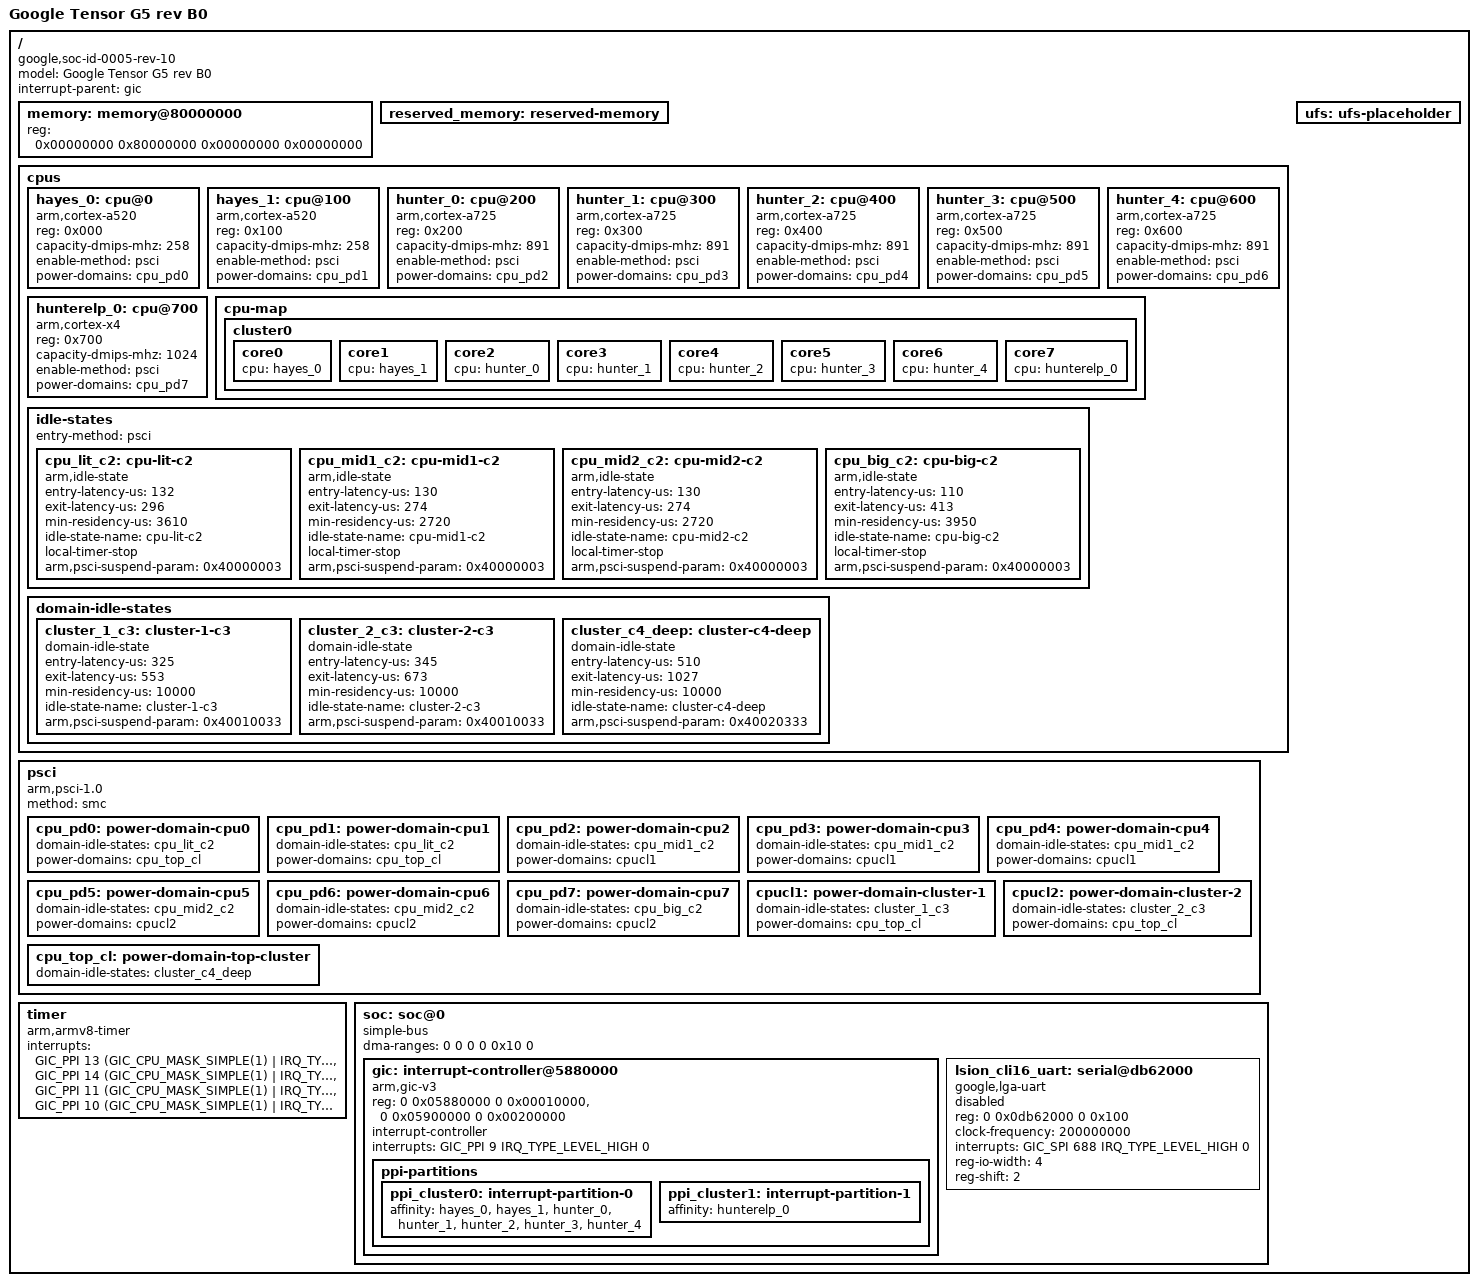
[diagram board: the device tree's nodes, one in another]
// SPDX-License-Identifier: GPL-2.0 OR BSD-3-Clause
/*
 * Google Tensor G5 (laguna) SoC rev B0
 *
 * Copyright 2024-2025 Google LLC.
 */

/dts-v1/;

#include <dt-bindings/interrupt-controller/arm-gic.h>
#include <dt-bindings/interrupt-controller/irq.h>

/ {
	model = "Google Tensor G5 rev B0";
	compatible = "google,soc-id-0005-rev-10", "google,lga";
	#address-cells = <2>;
	#size-cells = <2>;
	interrupt-parent = <&gic>;

	memory: memory@80000000 {
		device_type = "memory";
		/* We expect the bootloader to fill in the size */
		reg = <0x00000000 0x80000000 0x00000000 0x00000000>;
	};

	reserved_memory: reserved-memory {
		#address-cells = <2>;
		#size-cells = <2>;
		ranges;
	};

	cpus: cpus {
		#address-cells = <1>;
		#size-cells = <0>;

		hayes_0: cpu@0 {
			compatible = "arm,cortex-a520";
			reg = <0x000>;

			#cooling-cells = <2>;
			capacity-dmips-mhz = <258>;
			device_type = "cpu";
			enable-method = "psci";
			power-domain-names = "psci";
			power-domains = <&cpu_pd0>;
		};

		hayes_1: cpu@100 {
			compatible = "arm,cortex-a520";
			reg = <0x100>;

			#cooling-cells = <2>;
			capacity-dmips-mhz = <258>;
			device_type = "cpu";
			enable-method = "psci";
			power-domain-names = "psci";
			power-domains = <&cpu_pd1>;
		};

		hunter_0: cpu@200 {
			compatible = "arm,cortex-a725";
			reg = <0x200>;

			#cooling-cells = <2>;
			capacity-dmips-mhz = <891>;
			device_type = "cpu";
			enable-method = "psci";
			power-domain-names = "psci";
			power-domains = <&cpu_pd2>;
		};

		hunter_1: cpu@300 {
			compatible = "arm,cortex-a725";
			reg = <0x300>;

			#cooling-cells = <2>;
			capacity-dmips-mhz = <891>;
			device_type = "cpu";
			enable-method = "psci";
			power-domain-names = "psci";
			power-domains = <&cpu_pd3>;
		};

		hunter_2: cpu@400 {
			compatible = "arm,cortex-a725";
			reg = <0x400>;

			#cooling-cells = <2>;
			capacity-dmips-mhz = <891>;
			device_type = "cpu";
			enable-method = "psci";
			power-domain-names = "psci";
			power-domains = <&cpu_pd4>;
		};

		hunter_3: cpu@500 {
			compatible = "arm,cortex-a725";
			reg = <0x500>;

			#cooling-cells = <2>;
			capacity-dmips-mhz = <891>;
			device_type = "cpu";
			enable-method = "psci";
			power-domain-names = "psci";
			power-domains = <&cpu_pd5>;
		};

		hunter_4: cpu@600 {
			compatible = "arm,cortex-a725";
			reg = <0x600>;

			#cooling-cells = <2>;
			capacity-dmips-mhz = <891>;
			device_type = "cpu";
			enable-method = "psci";
			power-domain-names = "psci";
			power-domains = <&cpu_pd6>;
		};

		hunterelp_0: cpu@700 {
			compatible = "arm,cortex-x4";
			reg = <0x700>;

			#cooling-cells = <2>;
			capacity-dmips-mhz = <1024>;
			device_type = "cpu";
			enable-method = "psci";
			power-domain-names = "psci";
			power-domains = <&cpu_pd7>;
		};

		cpu-map {
			cluster0 {
				core0 {
					cpu = <&hayes_0>;
				};
				core1 {
					cpu = <&hayes_1>;
				};
				core2 {
					cpu = <&hunter_0>;
				};
				core3 {
					cpu = <&hunter_1>;
				};
				core4 {
					cpu = <&hunter_2>;
				};
				core5 {
					cpu = <&hunter_3>;
				};
				core6 {
					cpu = <&hunter_4>;
				};
				core7 {
					cpu = <&hunterelp_0>;
				};
			};
		};

		idle-states {
			entry-method = "psci";

			cpu_lit_c2: cpu-lit-c2 {
				compatible = "arm,idle-state";

				entry-latency-us = <132>;
				exit-latency-us = <296>;
				min-residency-us = <3610>;

				idle-state-name = "cpu-lit-c2";
				local-timer-stop;

				arm,psci-suspend-param = <0x40000003>;
			};

			cpu_mid1_c2: cpu-mid1-c2 {
				compatible = "arm,idle-state";

				entry-latency-us = <130>;
				exit-latency-us = <274>;
				min-residency-us = <2720>;

				idle-state-name = "cpu-mid1-c2";
				local-timer-stop;

				arm,psci-suspend-param = <0x40000003>;
			};

			cpu_mid2_c2: cpu-mid2-c2 {
				compatible = "arm,idle-state";

				entry-latency-us = <130>;
				exit-latency-us = <274>;
				min-residency-us = <2720>;

				idle-state-name = "cpu-mid2-c2";
				local-timer-stop;

				arm,psci-suspend-param = <0x40000003>;
			};

			cpu_big_c2: cpu-big-c2 {
				compatible = "arm,idle-state";

				entry-latency-us = <110>;
				exit-latency-us = <413>;
				min-residency-us = <3950>;

				idle-state-name = "cpu-big-c2";
				local-timer-stop;

				arm,psci-suspend-param = <0x40000003>;
			};
		};

		domain-idle-states {
			cluster_1_c3: cluster-1-c3 {
				compatible = "domain-idle-state";

				entry-latency-us = <325>;
				exit-latency-us = <553>;
				min-residency-us = <10000>;

				idle-state-name = "cluster-1-c3";

				arm,psci-suspend-param = <0x40010033>;
			};

			cluster_2_c3: cluster-2-c3 {
				compatible = "domain-idle-state";

				entry-latency-us = <345>;
				exit-latency-us = <673>;
				min-residency-us = <10000>;

				idle-state-name = "cluster-2-c3";

				arm,psci-suspend-param = <0x40010033>;
			};

			cluster_c4_deep: cluster-c4-deep {
				compatible = "domain-idle-state";

				entry-latency-us = <510>;
				exit-latency-us = <1027>;
				min-residency-us = <10000>;

				idle-state-name = "cluster-c4-deep";

				arm,psci-suspend-param = <0x40020333>;
			};
		};
	};

	psci {
		compatible = "arm,psci-1.0";
		method = "smc";

		cpu_pd0: power-domain-cpu0 {
			#power-domain-cells = <0>;
			domain-idle-states = <&cpu_lit_c2>;
			power-domains = <&cpu_top_cl>;
		};

		cpu_pd1: power-domain-cpu1 {
			#power-domain-cells = <0>;
			domain-idle-states =  <&cpu_lit_c2>;
			power-domains = <&cpu_top_cl>;
		};

		cpu_pd2: power-domain-cpu2 {
			#power-domain-cells = <0>;
			domain-idle-states =  <&cpu_mid1_c2>;
			power-domains = <&cpucl1>;
		};

		cpu_pd3: power-domain-cpu3 {
			#power-domain-cells = <0>;
			domain-idle-states =  <&cpu_mid1_c2>;
			power-domains = <&cpucl1>;
		};

		cpu_pd4: power-domain-cpu4 {
			#power-domain-cells = <0>;
			domain-idle-states =  <&cpu_mid1_c2>;
			power-domains = <&cpucl1>;
		};

		cpu_pd5: power-domain-cpu5 {
			#power-domain-cells = <0>;
			domain-idle-states =  <&cpu_mid2_c2>;
			power-domains = <&cpucl2>;
		};

		cpu_pd6: power-domain-cpu6 {
			#power-domain-cells = <0>;
			domain-idle-states =  <&cpu_mid2_c2>;
			power-domains = <&cpucl2>;
		};

		cpu_pd7: power-domain-cpu7 {
			#power-domain-cells = <0>;
			domain-idle-states =  <&cpu_big_c2>;
			power-domains = <&cpucl2>;
		};

		cpucl1: power-domain-cluster-1 {
			#power-domain-cells = <0>;
			domain-idle-states = <&cluster_1_c3>;
			power-domains = <&cpu_top_cl>;
		};

		cpucl2: power-domain-cluster-2 {
			#power-domain-cells = <0>;
			domain-idle-states = <&cluster_2_c3>;
			power-domains = <&cpu_top_cl>;
		};

		cpu_top_cl: power-domain-top-cluster {
			#power-domain-cells = <0>;
			domain-idle-states = <&cluster_c4_deep>;
		};
	};

	timer {
		compatible = "arm,armv8-timer";
		interrupts =
			<GIC_PPI 13 (GIC_CPU_MASK_SIMPLE(1) | IRQ_TYPE_LEVEL_LOW) 0>,
			<GIC_PPI 14 (GIC_CPU_MASK_SIMPLE(1) | IRQ_TYPE_LEVEL_LOW) 0>,
			<GIC_PPI 11 (GIC_CPU_MASK_SIMPLE(1) | IRQ_TYPE_LEVEL_LOW) 0>,
			<GIC_PPI 10 (GIC_CPU_MASK_SIMPLE(1) | IRQ_TYPE_LEVEL_LOW) 0>;
	};

	/*
	 * The Pixel bootloader considers it a fatal error if it doesn't find
	 * a `ufs0` alias so it can add calibration data to the node. Until
	 * the proper UFS controller node is added under the SoC, create a
	 * temporary node to make the bootloader happy.
	 */
	ufs: ufs-placeholder {
	};

	soc: soc@0 {
		compatible = "simple-bus";
		ranges = <0 0 0 0 0x10 0>;

		dma-ranges = <0 0 0 0 0x10 0>;

		#address-cells = <2>;
		#size-cells = <2>;

		gic: interrupt-controller@5880000 { /* TODO ask for CPU IPC CSR */
			compatible = "arm,gic-v3";
			reg = <0 0x05880000 0 0x00010000>,
			      <0 0x05900000 0 0x00200000>;
			ranges;

			#address-cells = <2>;
			#size-cells = <2>;

			#interrupt-cells = <4>;
			interrupt-controller;
			interrupts = <GIC_PPI 9 IRQ_TYPE_LEVEL_HIGH 0>;

			ppi-partitions {
				ppi_cluster0: interrupt-partition-0 {
					affinity = <&hayes_0 &hayes_1
						    &hunter_0 &hunter_1 &hunter_2
						    &hunter_3 &hunter_4>;
				};

				ppi_cluster1: interrupt-partition-1 {
					affinity = <&hunterelp_0>;
				};
			};
		};

		lsion_cli16_uart: serial@db62000 {
			compatible = "google,lga-uart", "snps,dw-apb-uart";
			reg = <0 0x0db62000 0 0x100>;

			clock-frequency = <200000000>;
			interrupts = <GIC_SPI 688 IRQ_TYPE_LEVEL_HIGH 0>;
			reg-io-width = <4>;
			reg-shift = <2>;

			status = "disabled";
		};
	};
};
